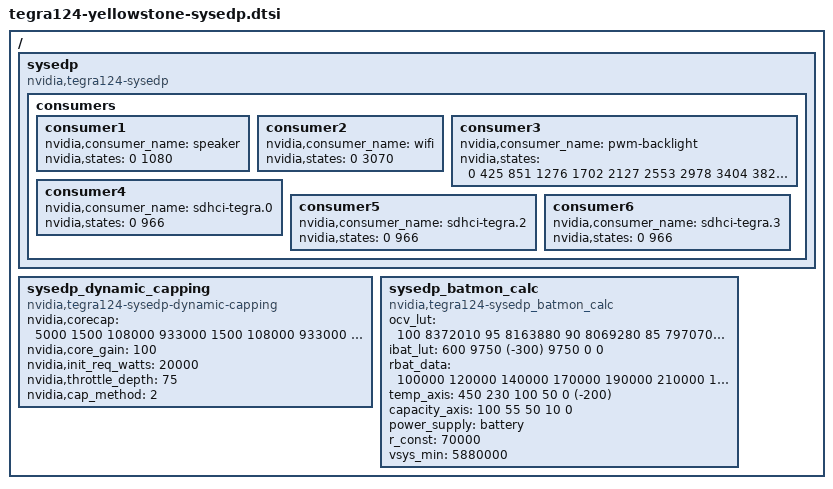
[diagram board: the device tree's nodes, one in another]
/*
 * arch/arm/boot/dts/tegra124-platforms/tegra124-yellowstone-sysedp-p1780-1000-a02.dtsi
 *
 * Copyright (c) 2014, NVIDIA CORPORATION.  All rights reserved.
 *
 * This program is free software; you can redistribute it and/or modify
 * it under the terms of the GNU General Public License as published by
 * the Free Software Foundation; either version 2 of the License, or
 * (at your option) any later version.
 *
 * This program is distributed in the hope that it will be useful, but WITHOUT
 * ANY WARRANTY; without even the implied warranty of MERCHANTABILITY or
 * FITNESS FOR A PARTICULAR PURPOSE.  See the GNU General Public License for
 * more details.
 *
 * You should have received a copy of the GNU General Public License along
 * with this program; if not, write to the Free Software Foundation, Inc.,
 * 51 Franklin Street, Fifth Floor, Boston, MA  02110-1301, USA.
 */

/ {
	sysedp {
		status = "okay";
		compatible = "nvidia,tegra124-sysedp";

		consumers {
			consumer1 {
				nvidia,consumer_name = "speaker";
				nvidia,states = <0 1080>;
			};
			consumer2 {
				nvidia,consumer_name = "wifi";
				nvidia,states = <0 3070>;
			};
			consumer3 {
				nvidia,consumer_name = "pwm-backlight";
				nvidia,states = <0 425 851 1276 1702 2127 2553 2978 3404 3829 4255>;
			};
			consumer4 {
				nvidia,consumer_name = "sdhci-tegra.0";
				nvidia,states = <0 966>;
			};
			consumer5 {
				nvidia,consumer_name = "sdhci-tegra.2";
				nvidia,states = <0 966>;
			};
			consumer6 {
				nvidia,consumer_name = "sdhci-tegra.3";
				nvidia,states = <0 966>;
			};
		};
	};

	sysedp_dynamic_capping {
		status = "okay";
		compatible = "nvidia,tegra124-sysedp-dynamic-capping";
		nvidia,corecap = <
			5000	1500	108000	933000	1500	108000	933000	1116 
			6000	3000	108000	933000	3000	108000	933000	2109 
			7000	4000	108000	933000	3000	180000	933000	2589 
			8000	5000	108000	933000	3000	252000	933000	3068 
			9000	6000	180000	933000	2500	396000	933000	3630 
			10000	7000	108000	933000	3500	396000	933000	4425 
			11000	7000	252000	933000	4000	468000	933000	5301 
			12000	8000	180000	933000	3000	540000	933000	5348 
			13000	9000	108000	933000	5000	540000	933000	6969 
			14000	10000	108000	933000	3500	612000	933000	6846 
			15000	10000	180000	933000	4000	648000	933000	7880 
			16000	11000	180000	933000	3500	684000	933000	8120 
			17000	12000	108000	933000	4000	708000	933000	9024 
			18000	12000	252000	933000	3000	756000	933000	9252 
			19000	12000	252000	933000	4000	756000	933000	10046 
			20000	12000	396000	933000	5000	756000	933000	10873 
			21000	12000	468000	933000	3500	804000	933000	10909 
			22000	12000	540000	933000	4000	804000	933000	11306 
			23000	12000	540000	933000	4000	853000	933000	12696 
			24000	12000	612000	933000	5000	853000	933000	13524 
			25000	12000	612000	933000	5000	853000	933000	13524 
			26000	12000	684000	933000	6000	853000	933000	14452 
			27000	12000	708000	933000	7000	853000	933000	15002 
			28000	12000	708000	933000	8000	853000	933000	16030 
			29000	12000	756000	933000	8000	853000	933000	16311 
			30000	12000	756000	933000	8000	853000	933000	16311 
			31000	12000	756000	933000	8000	853000	933000	16311 
			32000	12000	804000	933000	9000	853000	933000	16883 
			33000	12000	804000	933000	10000	853000	933000	17721 
		>;
		nvidia,core_gain = <100>;
		nvidia,init_req_watts = <20000>;
		nvidia,throttle_depth = <75>;
		nvidia,cap_method = <2>;
	};

	sysedp_batmon_calc {
		status = "okay";
		compatible = "nvidia,tegra124-sysedp_batmon_calc";
		ocv_lut = <
			100 8372010
			95 8163880
			90 8069280
			85 7970700
			80 7894100
			75 7820860
			70 7751890
			65 7691770
			60 7641110
			55 7598990
			50 7564200
			45 7534290
			40 7511410
			35 7491870
			30 7468380
			25 7435720
			20 7388720
			15 7338370
			10 7219650
			0 5999850
		>;
		ibat_lut = <
			600 9750
			(-300) 9750
			0 0
		>;
		rbat_data = <
			100000 120000 140000 170000 190000 210000
			100000 120000 150000 170000 190000 210000
			100000 130000 150000 170000 200000 210000
			110000 130000 160000 170000 200000 210000
			120000 140000 170000 180000 210000 220000
		>;
		temp_axis = <450 230 100 50 0 (-200)>;
		capacity_axis = <100 55 50 10 0>;
		power_supply = "battery";
		r_const = <70000>;
		vsys_min = <5880000>;
	};
};
